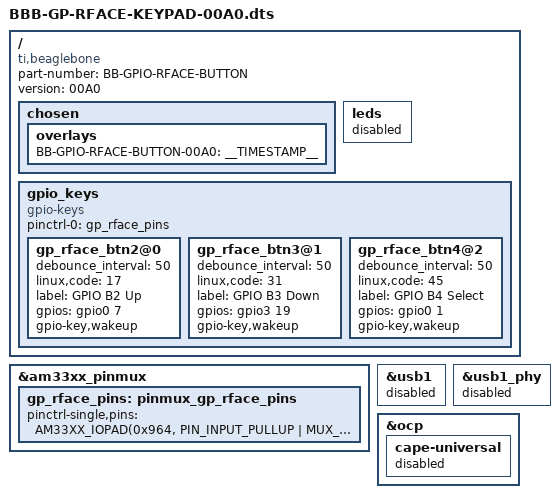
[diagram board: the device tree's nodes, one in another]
/*
 * Jensen Turner 11/3/2020
 */
/dts-v1/;
/plugin/;

#include <dt-bindings/board/am335x-bbw-bbb-base.h>
#include <dt-bindings/gpio/gpio.h>
#include <dt-bindings/pinctrl/am33xx.h>

/ {
	compatible = "ti,beaglebone", "ti,beaglebone-black", "ti,beaglebone-green";

	/* identification */
	part-number = "BB-GPIO-RFACE-BUTTON";
	version = "00A0";

	/*
	 * Helper to show loaded overlays under: /proc/device-tree/chosen/overlays/
	 */
	fragment@0 {
		target-path="/";
		__overlay__ {
			chosen {
				overlays {
					BB-GPIO-RFACE-BUTTON-00A0 = __TIMESTAMP__;
				};
			};
			leds {
			    status = "disabled";
			}
		};
	};

	fragment@1 {
		target = <&am33xx_pinmux>;
		__overlay__ {
		    gp_rface_pins: pinmux_gp_rface_pins {
		        pinctrl-single,pins = <
                    AM33XX_IOPAD(0x964, PIN_INPUT_PULLUP | MUX_MODE7) /* BTN2 ecap0_in_pwm0_out.gpio0_7 */
                    AM33XX_IOPAD(0x9a4, PIN_INPUT_PULLUP | MUX_MODE7) /* BTN3 mcasp0_fsr.gpio3_19 */
                    AM33XX_IOPAD(0x94c, PIN_INPUT_PULLUP | MUX_MODE7) /* BTN4 mdc.gpio0_1 */
		        >;
            };
		};
	};

	fragment@2 {
	    target = <&usb1>;
	    __overlay__ {
	        status = "disabled";
	    }
	}

	fragment@3 {
	    target = <&usb1_phy>;
	    __overlay__ {
	        status = "disabled";
	    }
	}

	fragment@10 {
		target= <&ocp>;
		__overlay__ {
			cape-universal {
				status = "disabled";
			};
		};
	};

	fragment@20 {
		target-path="/";
		__overlay__ {

			gpio_keys {
				compatible = "gpio-keys";
				pinctrl-names = "default";
				pinctrl-0 = <&gp_rface_pins>;

				#address-cells = <1>;
				#size-cells = <0>;

				gp_rface_btn2@0 {
				    /* Button 2 - V15 ecap0_in_pwm0_out P9_42 gpio0[7]. AM33XX_IOPAD(0x964, PIN_INPUT | MUX_MODE7) */
					debounce_interval = <50>;
					linux,code = <17>;
					label = "GPIO B2 Up";
					gpios = <&gpio0 7 0x0>;
					gpio-key,wakeup;
				};

				gp_rface_btn3@1 {
					/* Button 3 - W15 mcasp0_fsr P9_27 gpio3[19]. AM33XX_IOPAD(0x9a4, PIN_INPUT | MUX_MODE7) */
					debounce_interval = <50>;
					linux,code = <31>;
					label = "GPIO B3 Down";
					/*
					 * Grove Red/Yellow/Blue LED Button
					 * LOW valid/press
					 */
					gpios = <&gpio3 19 0x0>;
					gpio-key,wakeup;
				};

				gp_rface_btn4@2 {
				    /* Button 4 - W1 mdc gpio0[1] AM33XX_IOPAD(0x94c, PIN_INPUT | MUX_MODE7) */
				    debounce_interval = <50>;
					linux,code = <45>;
					label = "GPIO B4 Select";
					/*
					 * Grove Red/Yellow/Blue LED Button
					 * LOW valid/press
					 */
					gpios = <&gpio0 1 0x0>;
					gpio-key,wakeup;
				};
			};
		};
	};
};
